# ATmega328PB device description
Architecture: AVR8; Family: megaAVR
Registers are 8-bit, access not given, no defined reset value unless marked. A register's access mark holds for its fields unless they carry their own. Offsets are from the block's base; [hi:lo] are bit positions; 'fields as' and 'values as' point back to an identical list.

## AC
Instances: AC 0x00
0x4F ACSRB — Analog Comparator Control And Status Register-B
  [0] ACOE — Analog Comparator Output Enable
0x50 ACSRA — Analog Comparator Control And Status Register-A
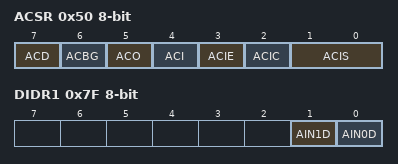
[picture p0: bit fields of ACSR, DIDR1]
0x50 ACSR — Analog Comparator Control And Status Register
  [7] ACD — Analog Comparator Disable
  [6] ACBG — Analog Comparator Bandgap Select
  [5] ACO — Analog Compare Output
  [4] ACI — Analog Comparator Interrupt Flag
  [3] ACIE — Analog Comparator Interrupt Enable
  [2] ACIC — Analog Comparator Input Capture Enable
  [1:0] ACIS — Analog Comparator Interrupt Mode Select bits
    0=Interrupt on Toggle; 2=Interrupt on Falling Edge; 3=Interrupt on Rising Edge
0x7F DIDR1 — Digital Input Disable Register 1
  [1] AIN1D — AIN1 Digital Input Disable
  [0] AIN0D — AIN0 Digital Input Disable

## PORTB
Instances: PORTB 0x00
0x23 PINB — Port B Input Pins
0x24 DDRB — Port B Data Direction Register
0x25 PORTB — Port B Data Register

## PORTC
Instances: PORTC 0x00
0x26 PINC bits used 6:0 — Port C Input Pins
0x27 DDRC bits used 6:0 — Port C Data Direction Register
0x28 PORTC bits used 6:0 — Port C Data Register

## PORTD
Instances: PORTD 0x00
0x29 PIND — Port D Input Pins
0x2A DDRD — Port D Data Direction Register
0x2B PORTD — Port D Data Register

## PORTE
Instances: PORTE 0x00
0x2C PINE bits used 3:0 — Port E Input Pins
0x2D DDRE bits used 3:0 — Port E Data Direction Register
0x2E PORTE bits used 3:0 — Port E Data Register

## TC0 (TC8 module)
Instances: TC0 0x00
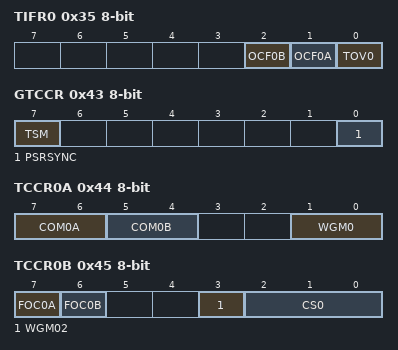
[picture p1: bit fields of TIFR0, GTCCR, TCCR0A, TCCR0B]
0x35 TIFR0 — Timer/Counter0 Interrupt Flag register
  [2] OCF0B — Timer/Counter0 Output Compare Flag 0B
  [1] OCF0A — Timer/Counter0 Output Compare Flag 0A
  [0] TOV0 — Timer/Counter0 Overflow Flag
0x43 GTCCR — General Timer/Counter Control Register
  [7] TSM — Timer/Counter Synchronization Mode
  [0] PSRSYNC — Prescaler Reset Timer/Counter1 and Timer/Counter0
0x44 TCCR0A — Timer/Counter Control Register A
  [7:6] COM0A — Compare Output Mode, Phase Correct PWM Mode
  [5:4] COM0B — Compare Output Mode, Fast PWM
  [1:0] WGM0 — Waveform Generation Mode
0x45 TCCR0B — Timer/Counter Control Register B
  [7] FOC0A — Force Output Compare A
  [6] FOC0B — Force Output Compare B
  [3] WGM02
  [2:0] CS0 — Clock Select
    0=No Clock Source (Stopped); 1=Running, No Prescaling; 2=Running, CLK/8; 3=Running, CLK/64; 4=Running, CLK/256; 5=Running, CLK/1024; 6=Running, ExtClk Tx Falling Edge; 7=Running, ExtClk Tx Rising Edge
0x46 TCNT0 — Timer/Counter0
0x47 OCR0A — Timer/Counter0 Output Compare Register
0x48 OCR0B — Timer/Counter0 Output Compare Register
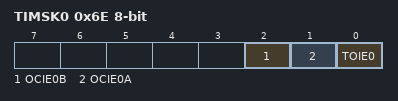
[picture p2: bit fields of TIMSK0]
0x6E TIMSK0 — Timer/Counter0 Interrupt Mask Register
  [2] OCIE0B — Timer/Counter0 Output Compare Match B Interrupt Enable
  [1] OCIE0A — Timer/Counter0 Output Compare Match A Interrupt Enable
  [0] TOIE0 — Timer/Counter0 Overflow Interrupt Enable

## EXINT
Instances: EXINT 0x00
0x3B PCIFR — Pin Change Interrupt Flag Register
  [3:0] PCIF — Pin Change Interrupt Flags
0x3C EIFR — External Interrupt Flag Register
  [1:0] INTF — External Interrupt Flags
0x3D EIMSK — External Interrupt Mask Register
  [1:0] INT — External Interrupt Request 1 Enable
0x68 PCICR — Pin Change Interrupt Control Register
  [3:0] PCIE — Pin Change Interrupt Enables
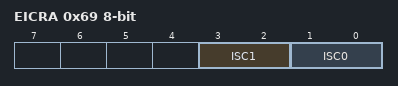
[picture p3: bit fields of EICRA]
0x69 EICRA — External Interrupt Control Register
  [3:2] ISC1 — External Interrupt Sense Control 1 Bits
    0=Low Level of INTX; 1=Any Logical Change of INTX; 2=Falling Edge of INTX; 3=Rising Edge of INTX
  [1:0] ISC0 — External Interrupt Sense Control 0 Bits
    values as ISC1
0x6B PCMSK0 — Pin Change Mask Register 0
  [7:0] PCINT — Pin Change Enable Masks
0x6C PCMSK1 — Pin Change Mask Register 1
  [6:0] PCINT (bit 8 of the value upward) — Pin Change Enable Masks
0x6D PCMSK2 — Pin Change Mask Register 2
  [7:0] PCINT (bit 16 of the value upward) — Pin Change Enable Masks
0x73 PCMSK3 — Pin Change Mask Register 3
  [3:0] PCINT (bit 24 of the value upward) — Pin Change Enable Masks
